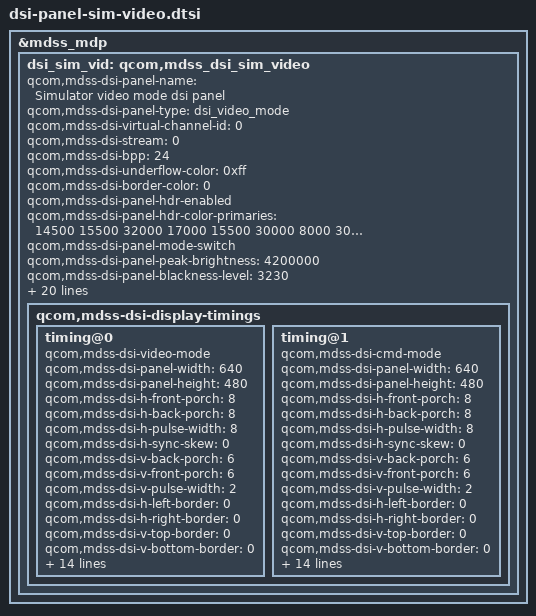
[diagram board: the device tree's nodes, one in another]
/* Copyright (c) 2012-2015, 2017-2020, The Linux Foundation. All rights reserved.
 *
 * This program is free software; you can redistribute it and/or modify
 * it under the terms of the GNU General Public License version 2 and
 * only version 2 as published by the Free Software Foundation.
 *
 * This program is distributed in the hope that it will be useful,
 * but WITHOUT ANY WARRANTY; without even the implied warranty of
 * MERCHANTABILITY or FITNESS FOR A PARTICULAR PURPOSE.  See the
 * GNU General Public License for more details.
 */

&mdss_mdp {
	dsi_sim_vid: qcom,mdss_dsi_sim_video {
		qcom,mdss-dsi-panel-name = "Simulator video mode dsi panel";
		qcom,mdss-dsi-panel-type = "dsi_video_mode";
		qcom,mdss-dsi-virtual-channel-id = <0>;
		qcom,mdss-dsi-stream = <0>;
		qcom,mdss-dsi-bpp = <24>;
		qcom,mdss-dsi-underflow-color = <0xff>;
		qcom,mdss-dsi-border-color = <0>;
		qcom,mdss-dsi-panel-hdr-enabled;
		qcom,mdss-dsi-panel-hdr-color-primaries = <14500 15500 32000
			17000 15500 30000 8000 3000>;
		qcom,mdss-dsi-panel-mode-switch;
		qcom,mdss-dsi-panel-peak-brightness = <4200000>;
		qcom,mdss-dsi-panel-blackness-level = <3230>;
		qcom,mdss-dsi-traffic-mode = "non_burst_sync_event";
		qcom,mdss-dsi-bllp-eof-power-mode;
		qcom,mdss-dsi-bllp-power-mode;
		qcom,mdss-dsi-lane-0-state;
		qcom,mdss-dsi-lane-1-state;
		qcom,mdss-dsi-lane-2-state;
		qcom,mdss-dsi-lane-3-state;
		qcom,mdss-dsi-t-clk-post = <0x04>;
		qcom,mdss-dsi-t-clk-pre = <0x1b>;
		qcom,mdss-dsi-dma-trigger = "trigger_sw";
		qcom,mdss-dsi-mdp-trigger = "none";
		qcom,mdss-dsi-reset-sequence = <1 0>, <0 0>, <1 0>;
		qcom,panel-ack-disabled;
		qcom,mdss-dsi-te-pin-select = <1>;
		qcom,mdss-dsi-wr-mem-start = <0x2c>;
		qcom,mdss-dsi-wr-mem-continue = <0x3c>;
		qcom,mdss-dsi-te-dcs-command = <1>;
		qcom,mdss-dsi-te-check-enable;
		qcom,mdss-dsi-te-using-wd;
		qcom,mdss-dsi-display-timings {
			timing@0{
				qcom,mdss-dsi-video-mode;
				qcom,mdss-dsi-panel-width = <640>;
				qcom,mdss-dsi-panel-height = <480>;
				qcom,mdss-dsi-h-front-porch = <8>;
				qcom,mdss-dsi-h-back-porch = <8>;
				qcom,mdss-dsi-h-pulse-width = <8>;
				qcom,mdss-dsi-h-sync-skew = <0>;
				qcom,mdss-dsi-v-back-porch = <6>;
				qcom,mdss-dsi-v-front-porch = <6>;
				qcom,mdss-dsi-v-pulse-width = <2>;
				qcom,mdss-dsi-h-left-border = <0>;
				qcom,mdss-dsi-h-right-border = <0>;
				qcom,mdss-dsi-v-top-border = <0>;
				qcom,mdss-dsi-v-bottom-border = <0>;
				qcom,mdss-dsi-panel-framerate = <60>;
				qcom,mdss-dsi-panel-timings =
					[00 00 00 00 00 00 00 00 00 00 00 00];
				qcom,mdss-dsi-on-command =
					[32 01 00 00 00 00 02 00 00];
				qcom,mdss-dsi-off-command =
					[22 01 00 00 00 00 02 00 00];
				qcom,mdss-dsi-on-command-state = "dsi_lp_mode";
				qcom,mdss-dsi-off-command-state = "dsi_lp_mode";
				qcom,mdss-dsi-h-sync-pulse = <0>;
				qcom,cmd-to-video-mode-post-switch-commands = [
					32 01 00 00 00 00 02 00 00];
			    qcom,cmd-to-video-mode-post-switch-commands-state =
					"dsi_lp_mode";
			};
			timing@1{
				qcom,mdss-dsi-cmd-mode;
				qcom,mdss-dsi-panel-width = <640>;
				qcom,mdss-dsi-panel-height = <480>;
				qcom,mdss-dsi-h-front-porch = <8>;
				qcom,mdss-dsi-h-back-porch = <8>;
				qcom,mdss-dsi-h-pulse-width = <8>;
				qcom,mdss-dsi-h-sync-skew = <0>;
				qcom,mdss-dsi-v-back-porch = <6>;
				qcom,mdss-dsi-v-front-porch = <6>;
				qcom,mdss-dsi-v-pulse-width = <2>;
				qcom,mdss-dsi-h-left-border = <0>;
				qcom,mdss-dsi-h-right-border = <0>;
				qcom,mdss-dsi-v-top-border = <0>;
				qcom,mdss-dsi-v-bottom-border = <0>;
				qcom,mdss-dsi-panel-framerate = <60>;
				qcom,mdss-dsi-panel-timings =
					[00 00 00 00 00 00 00 00 00 00 00 00];
				qcom,mdss-dsi-on-command =
					[32 01 00 00 00 00 02 00 00];
				qcom,mdss-dsi-off-command =
					[22 01 00 00 00 00 02 00 00];
				qcom,mdss-dsi-on-command-state = "dsi_lp_mode";
				qcom,mdss-dsi-off-command-state = "dsi_lp_mode";
				qcom,mdss-dsi-h-sync-pulse = <0>;
				qcom,video-to-cmd-mode-post-switch-commands = [
					32 01 00 00 00 00 02 00 00];
			    qcom,video-to-cmd-mode-post-switch-commands-state =
					 "dsi_lp_mode";
			};
		};
	};
};
